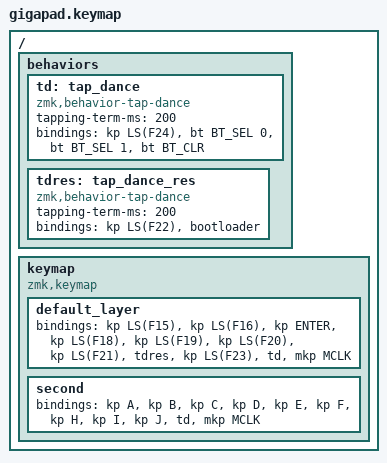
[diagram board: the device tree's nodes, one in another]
#include <behaviors.dtsi>
#include <dt-bindings/zmk/keys.h>
#include <dt-bindings/zmk/bt.h>
#include <dt-bindings/zmk/outputs.h>
#include <dt-bindings/zmk/behaviors.h>
#include <dt-bindings/zmk/pointing.h>


/ {

    behaviors {
        td: tap_dance {
            compatible = "zmk,behavior-tap-dance";
            #binding-cells = <0>;
            tapping-term-ms = <200>;
            bindings = <&kp LS(F24)>, <&bt BT_SEL 0>, <&bt BT_SEL 1>, <&bt BT_CLR>;
        };
        tdres: tap_dance_res {
            compatible = "zmk,behavior-tap-dance";
            #binding-cells = <0>;
            tapping-term-ms = <200>;
            bindings = <&kp LS(F22)>, <&bootloader>;
        };
    };

    keymap {
        compatible = "zmk,keymap";

        default_layer {
            bindings = <
                &kp LS(F15)
                &kp LS(F16)
                &kp ENTER
                &kp LS(F18)
                &kp LS(F19)
                &kp LS(F20)
                &kp LS(F21)
                &tdres
                &kp LS(F23)
                &td
                &mkp MCLK
            >;
        };

        second {
            bindings = <
                &kp A
                &kp B
                &kp C
                &kp D
                &kp E
                &kp F
                &kp H
                &kp I
                &kp J
                &td
                &mkp MCLK
            >;
        };


    };
};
